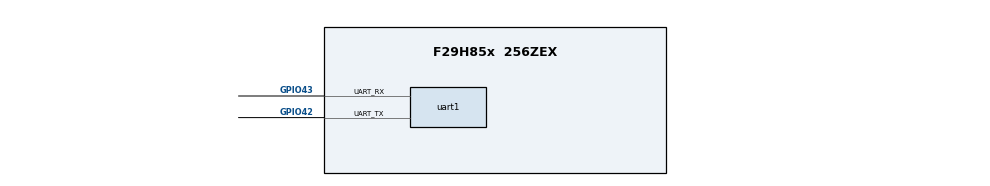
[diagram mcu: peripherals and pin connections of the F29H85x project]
/**
 * @cliArgs --device "F29H85x" --package "256ZEX" --part "F29H85x_256ZEX" --context "CPU1" --product "MCU_SDK_F29H85x@1.02.02.00"
 * @versions {"tool":"1.25.0+4237"}
 */

    
const divider15       = system.clockTree["PLL_REFDIV"];
divider15.divideValue = 1;

const multiplier1         = system.clockTree["PLL_IMULT"];
multiplier1.multiplyValue = 40;

const mux7       = system.clockTree["OSCCLKSRCSEL"];
mux7.inputSelect = "INTOSC2";

/**
 * Import the modules used in this configuration.
 */
const jtag  = scripting.addModule("/driverlib/jtag.js");
const uart  = scripting.addModule("/driverlib/uart.js");
const uart1 = uart.addInstance();

/**
 * Write custom configuration values to the imported modules.
 */

uart1.$name                    = "myUART0";
uart1.baudSelect               = "115200";
uart1.enabledInterrupts        = ["UART_INT_RX"];
uart1.registerInterrupts       = true;
uart1.uart.$assign             = "UARTA";
uart1.uart.uart_txPin.$assign  = "GPIO42";
uart1.uart.uart_rxPin.$assign  = "GPIO43";
uart1.txQual.$name             = "myGPIOQUAL0";
uart1.rxQual.$name             = "myGPIOQUAL1";
uart1.periphClock.$name        = "driverlib_perClock0";
uart1.periphConfig.$name       = "driverlib_perConfig0";
uart1.uartInt.interruptHandler = "UART_RX_IntHandler";
